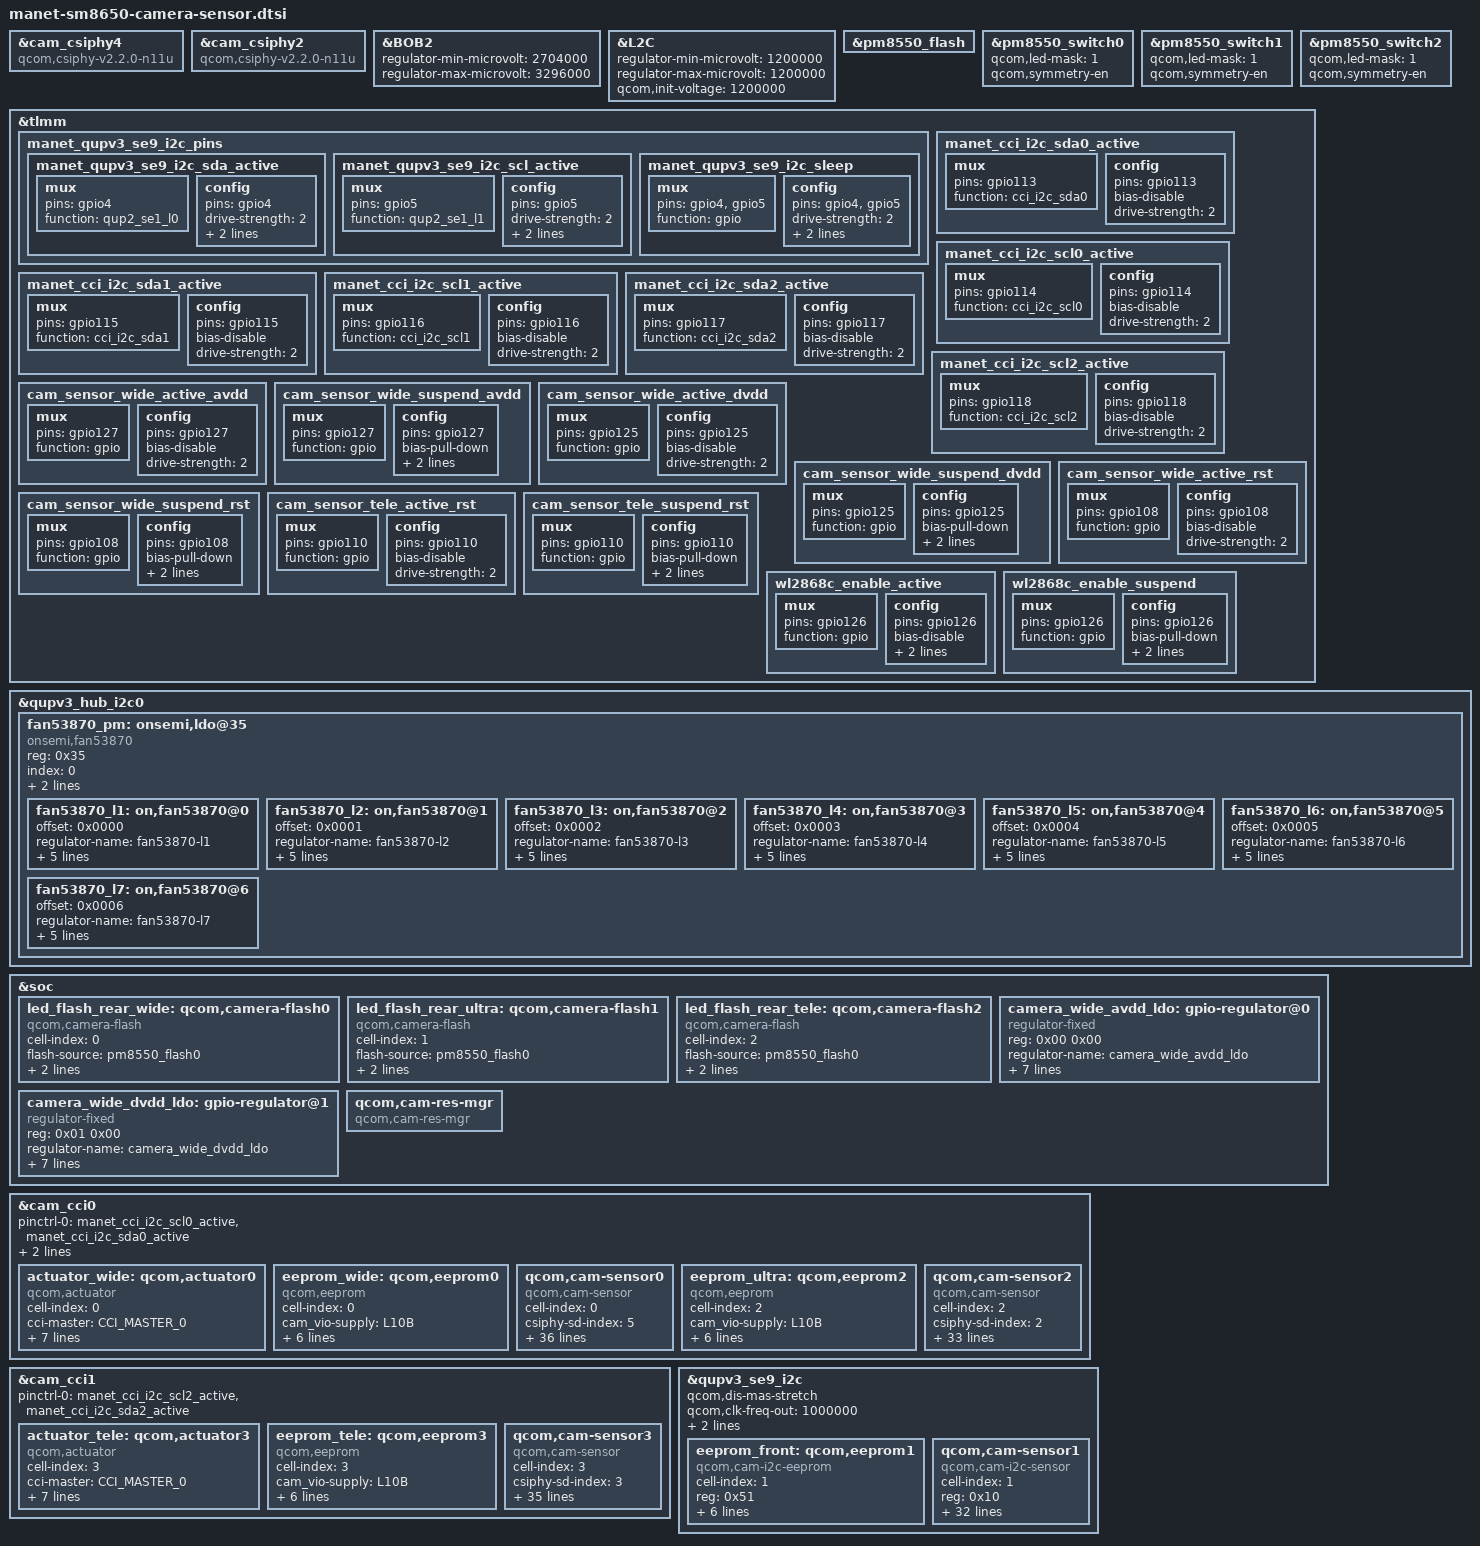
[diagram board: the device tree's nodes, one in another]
#include <dt-bindings/msm-camera.h>

//front
&cam_csiphy4 {
	compatible = "qcom,csiphy-v2.2.0-n11u", "qcom,csiphy";
};

//ultra
&cam_csiphy2 {
	compatible = "qcom,csiphy-v2.2.0-n11u", "qcom,csiphy";
};

&BOB2 {
	regulator-min-microvolt = <2704000>;
	regulator-max-microvolt = <3296000>;
};

&L2C {
	regulator-min-microvolt = <1200000>;
	regulator-max-microvolt = <1200000>;
	qcom,init-voltage = <1200000>;
};

&pm8550_flash {
	status = "ok";
};

&pm8550_switch0 {
	qcom,led-mask = <1>;
	qcom,symmetry-en;
};

&pm8550_switch1 {
	qcom,led-mask = <1>;
	qcom,symmetry-en;
};

&pm8550_switch2 {
	qcom,led-mask = <1>;
	qcom,symmetry-en;
};

&tlmm {
	manet_qupv3_se9_i2c_pins: manet_qupv3_se9_i2c_pins {
		manet_qupv3_se9_i2c_sda_active: manet_qupv3_se9_i2c_sda_active {
			mux {
				pins = "gpio4";
				function = "qup2_se1_l0";
			};

			config {
				pins = "gpio4";
				drive-strength = <2>;
				bias-disable; /* NO PULL */
				qcom,apps;
			};
		};

		manet_qupv3_se9_i2c_scl_active: manet_qupv3_se9_i2c_scl_active {
			mux {
				pins = "gpio5";
				function = "qup2_se1_l1";
			};

			config {
				pins = "gpio5";
				drive-strength = <2>;
				bias-disable; /* NO PULL */
				qcom,apps;
			};
		};

		manet_qupv3_se9_i2c_sleep: manet_qupv3_se9_i2c_sleep {
			mux {
				pins = "gpio4", "gpio5";
				function = "gpio";
			};

			config {
				pins = "gpio4", "gpio5";
				drive-strength = <2>;
				bias-pull-down;
				qcom,remote;
			};
		};
	};


	manet_cci_i2c_sda0_active: manet_cci_i2c_sda0_active {
		mux {
			/* CLK, DATA */
			pins = "gpio113";
			function = "cci_i2c_sda0";
		};

		config {
			pins = "gpio113";
			bias-disable; /* NO PULL */
			drive-strength = <2>; /* 2 MA */
		};
	};

	manet_cci_i2c_scl0_active: manet_cci_i2c_scl0_active {
		mux {
			/* CLK, DATA */
			pins = "gpio114";
			function = "cci_i2c_scl0";
		};

		config {
			pins = "gpio114";
			bias-disable; /* NO PULL */
			drive-strength = <2>; /* 2 MA */
		};
	};

	manet_cci_i2c_sda1_active: manet_cci_i2c_sda1_active {
		mux {
			/* CLK, DATA */
			pins = "gpio115";
			function = "cci_i2c_sda1";
		};

		config {
			pins = "gpio115";
			bias-disable; /* NO PULL */
			drive-strength = <2>; /* 2 MA */
		};
	};

	manet_cci_i2c_scl1_active: manet_cci_i2c_scl1_active {
		mux {
			/* CLK, DATA */
			pins = "gpio116";
			function = "cci_i2c_scl1";
		};

		config {
			pins = "gpio116";
			bias-disable; /* NO PULL */
			drive-strength = <2>; /* 2 MA */
		};
	};

	manet_cci_i2c_sda2_active: manet_cci_i2c_sda2_active {
		mux {
			/* CLK, DATA */
			pins = "gpio117";
			function = "cci_i2c_sda2";
		};

		config {
			pins = "gpio117";
			bias-disable; /* NO PULL */
			drive-strength = <2>; /* 2 MA */
		};
	};

	manet_cci_i2c_scl2_active: manet_cci_i2c_scl2_active {
		mux {
			/* CLK, DATA */
			pins = "gpio118";
			function = "cci_i2c_scl2";
		};

		config {
			pins = "gpio118";
			bias-disable; /* NO PULL */
			drive-strength = <2>; /* 2 MA */
		};
	};

	// WIDE AVDD PINCTL
	cam_sensor_wide_active_avdd: cam_sensor_wide_active_avdd {
		mux {
			pins = "gpio127";
			function = "gpio";
		};

		config {
			pins = "gpio127";
			bias-disable; /* No PULL */
			drive-strength = <2>; /* 2 MA */
		};
	};

	cam_sensor_wide_suspend_avdd: cam_sensor_wide_suspend_avdd {
		mux {
			pins = "gpio127";
			function = "gpio";
		};

		config {
			pins = "gpio127";
			bias-pull-down; /* PULL DOWN */
			drive-strength = <2>; /* 2 MA */
			output-low;
		};
	};

	// WIDE DVDD PINCTL
	cam_sensor_wide_active_dvdd: cam_sensor_wide_active_dvdd {
		mux {
			pins = "gpio125";
			function = "gpio";
		};

		config {
			pins = "gpio125";
			bias-disable; /* No PULL */
			drive-strength = <2>; /* 2 MA */
		};
	};

	cam_sensor_wide_suspend_dvdd: cam_sensor_wide_suspend_dvdd {
		mux {
			pins = "gpio125";
			function = "gpio";
		};

		config {
			pins = "gpio125";
			bias-pull-down; /* PULL DOWN */
			drive-strength = <2>; /* 2 MA */
			output-low;
		};
	};

	// WIDE RST
	cam_sensor_wide_active_rst: cam_sensor_wide_active_rst {
		mux {
			pins = "gpio108";
			function = "gpio";
		};

		config {
			pins = "gpio108";
			bias-disable; /* No PULL */
			drive-strength = <2>; /* 2 MA */
		};
	};

	cam_sensor_wide_suspend_rst: cam_sensor_wide_suspend_rst {
		mux {
			pins = "gpio108";
			function = "gpio";
		};

		config {
			pins = "gpio108";
			bias-pull-down; /* PULL DOWN */
			drive-strength = <2>; /* 2 MA */
			output-low;
		};
	};

	// TELE RST
	cam_sensor_tele_active_rst: cam_sensor_tele_active_rst {
		mux {
			pins = "gpio110";
			function = "gpio";
		};

		config {
			pins = "gpio110";
			bias-disable; /* No PULL */
			drive-strength = <2>; /* 2 MA */
		};
	};

	cam_sensor_tele_suspend_rst: cam_sensor_tele_suspend_rst {
		mux {
			pins = "gpio110";
			function = "gpio";
		};

		config {
			pins = "gpio110";
			bias-pull-down; /* PULL DOWN */
			drive-strength = <2>; /* 2 MA */
			output-low;
		};
	};

	// WL2868C RST
	wl2868c_enable_active: wl2868c_enable_active {
		mux {
			pins = "gpio126";
			function = "gpio";
		};

		config {
			pins = "gpio126";
			bias-disable; /* No PULL */
			drive-strength = <2>; /* 2 MA */
			output-high;
		};
	};

	wl2868c_enable_suspend: wl2868c_enable_suspend {
		mux {
			pins = "gpio126";
			function = "gpio";
		};

		config {
			pins = "gpio126";
			bias-pull-down; /* PULL DOWN */
			drive-strength = <2>; /* 2 MA */
			output-low;
		};
	};
};

&qupv3_hub_i2c0 {
	#address-cells = <1>;
	#size-cells = <0>;
	status = "ok";

	fan53870_pm:onsemi,ldo@35 {
		compatible = "onsemi,fan53870";
		reg = <0x35>;/*slave address*/
		index = <0>;
		pinctrl-names = "wl2868c_enable", "wl2868c_disable";
		pinctrl-0 = <&wl2868c_enable_active>;
		pinctrl-1 = <&wl2868c_enable_suspend>;

		fan53870_l1:on,fan53870@0{
			offset = /bits/ 16 <0x0000>;
			regulator-name ="fan53870-l1";
			regulator-min-microvolt = <528000>;
			regulator-max-microvolt = <1504000>;
			min-dropout-voltage = <225000>;
			init-voltage = <1200000>;
			iout_ua = <650000>;
		};

		fan53870_l2:on,fan53870@1{
			offset = /bits/ 16 <0x0001>;
			regulator-name ="fan53870-l2";
			regulator-min-microvolt = <528000>;
			regulator-max-microvolt = <1504000>;
			min-dropout-voltage = <225000>;
			init-voltage = <1200000>;
			iout_ua = <650000>;
		};

		fan53870_l3:on,fan53870@2{
			offset = /bits/ 16 <0x0002>;
			regulator-name ="fan53870-l3";
			regulator-min-microvolt = <1504000>;
			regulator-max-microvolt = <3400000>;
			min-dropout-voltage = <200000>;
			init-voltage = <2800000>;
			iout_ua = <650000>;
		};

		fan53870_l4:on,fan53870@3{
			offset = /bits/ 16 <0x0003>;
			regulator-name ="fan53870-l4";
			regulator-min-microvolt = <1504000>;
			regulator-max-microvolt = <3400000>;
			min-dropout-voltage = <200000>;
			init-voltage = <2800000>;
			iout_ua = <650000>;
		};

		fan53870_l5:on,fan53870@4{
			offset = /bits/ 16 <0x0004>;
			regulator-name ="fan53870-l5";
			regulator-min-microvolt = <1504000>;
			regulator-max-microvolt = <3400000>;
			min-dropout-voltage = <300000>;
			init-voltage = <2700000>;
			iout_ua = <650000>;
		};

		fan53870_l6:on,fan53870@5{
			offset = /bits/ 16 <0x0005>;
			regulator-name ="fan53870-l6";
			regulator-min-microvolt = <1504000>;
			regulator-max-microvolt = <3400000>;
			min-dropout-voltage = <300000>;
			init-voltage = <2800000>;
			iout_ua = <650000>;
		};

		fan53870_l7:on,fan53870@6{
			offset = /bits/ 16 <0x0006>;
			regulator-name ="fan53870-l7";
			regulator-min-microvolt = <1504000>;
			regulator-max-microvolt = <3400000>;
			min-dropout-voltage = <300000>;
			init-voltage = <2800000>;
			iout_ua = <650000>;
		};
	};
};

&soc {
	led_flash_rear_wide: qcom,camera-flash0 {
		cell-index = <0>;
		compatible = "qcom,camera-flash";
		flash-source = <&pm8550_flash0>;
		torch-source = <&pm8550_torch0>;
		switch-source = <&pm8550_switch0>;
		status = "ok";
	};

	led_flash_rear_ultra: qcom,camera-flash1 {
		cell-index = <1>;
		compatible = "qcom,camera-flash";
		flash-source = <&pm8550_flash0>;
		torch-source = <&pm8550_torch0>;
		switch-source = <&pm8550_switch0>;
		status = "ok";
	};

	led_flash_rear_tele: qcom,camera-flash2 {
		cell-index = <2>;
		compatible = "qcom,camera-flash";
		flash-source = <&pm8550_flash0>;
		torch-source = <&pm8550_torch0>;
		switch-source = <&pm8550_switch0>;
		status = "ok";
	};

	camera_wide_avdd_ldo: gpio-regulator@0 {
		compatible = "regulator-fixed";
		reg = <0x00 0x00>;
		regulator-name = "camera_wide_avdd_ldo";
		regulator-min-microvolt = <2800000>;
		regulator-max-microvolt = <2800000>;
		regulator-enable-ramp-delay = <100>;
		enable-active-high;
		gpio = <&tlmm 127 0>;
		pinctrl-names = "wide_avdd_active", "wide_avdd_suspend";
		pinctrl-0 = <&cam_sensor_wide_active_avdd
					 &cam_sensor_wide_suspend_avdd>;
	};

	camera_wide_dvdd_ldo: gpio-regulator@1 {
		compatible = "regulator-fixed";
		reg = <0x01 0x00>;
		regulator-name = "camera_wide_dvdd_ldo";
		regulator-min-microvolt = <1104000>;
		regulator-max-microvolt = <1104000>;
		regulator-enable-ramp-delay = <100>;
		enable-active-high;
		gpio = <&tlmm 125 0>;
		pinctrl-names = "wide_dvdd_active", "wide_dvdd_suspend";
		pinctrl-0 = <&cam_sensor_wide_active_dvdd
					 &cam_sensor_wide_suspend_dvdd>;
	};

	qcom,cam-res-mgr {
		compatible = "qcom,cam-res-mgr";
		status = "ok";
	};
};

&cam_cci0 {
	pinctrl-0 = <&manet_cci_i2c_scl0_active &manet_cci_i2c_sda0_active>;
	pinctrl-2 = <&manet_cci_i2c_scl1_active &manet_cci_i2c_sda1_active>;

	actuator_wide: qcom,actuator0 {
		cell-index = <0>;
		compatible = "qcom,actuator";
		cci-master = <CCI_MASTER_0>;
		cam_vaf-supply = <&fan53870_l7>;
		cam_vio-supply = <&L10B>;
		regulator-names = "cam_vaf", "cam_vio";
		rgltr-cntrl-support;
		rgltr-min-voltage = <3104000 1800000>;
		rgltr-max-voltage = <3104000 1800000>;
		rgltr-load-current = <103000 20000>;
	};

	eeprom_wide: qcom,eeprom0 {
		cell-index = <0>;
		compatible = "qcom,eeprom";
		cam_vio-supply = <&L10B>;
		regulator-names = "cam_vio";
		rgltr-cntrl-support;
		rgltr-min-voltage = <1800000>;
		rgltr-max-voltage = <1800000>;
		rgltr-load-current = <150000>;
		cci-master = <CCI_MASTER_0>;
		status = "ok";
	};

	// Wide Sensor
	qcom,cam-sensor0 {
		cell-index = <0>;
		compatible = "qcom,cam-sensor";
		csiphy-sd-index = <5>;
		led-flash-src = <&led_flash_rear_wide>;
		eeprom-src = <&eeprom_wide>;
		actuator-src = <&actuator_wide>;
		sensor-position-roll = <90>;
		sensor-position-pitch = <0>;
		sensor-position-yaw = <180>;
		cam_vana-supply = <&camera_wide_avdd_ldo>;
		cam_vio-supply = <&L10B>;
		cam_vdig-supply = <&camera_wide_dvdd_ldo>;
		cam_vaf-supply = <&fan53870_l7>;
		cam_clk-supply = <&cam_cc_titan_top_gdsc>;
		cam_bob2-supply = <&BOB2>;
		regulator-names = "cam_vana", "cam_vio", "cam_vdig",
			"cam_vaf", "cam_clk", "cam_bob2";
		rgltr-cntrl-support;
		rgltr-min-voltage = <2800000 1800000 1104000 3104000 0 2704000>;
		rgltr-max-voltage = <2800000 1800000 1104000 3104000 0 3296000>;
		rgltr-load-current = <150000 150000 150000 103000 0 2000000>;
		gpio-no-mux = <0>;
		pinctrl-names = "cam_default", "cam_suspend";
		pinctrl-0 = <&cam_sensor_mclk0_active
			&cam_sensor_wide_active_rst>;
		pinctrl-1 = <&cam_sensor_mclk0_suspend
			&cam_sensor_wide_suspend_rst>;
		gpios = <&tlmm 100 0>, <&tlmm 108 0>;
		gpio-reset = <1>;
		gpio-req-tbl-num = <0 1>;
		gpio-req-tbl-flags = <1 0>;
		gpio-req-tbl-label = "CAMIF_MCLK0", "CAM_RESET_WIDE";
		cci-master = <CCI_MASTER_0>;
		clocks = <&camcc CAM_CC_MCLK0_CLK>;
		clock-names = "cam_clk";
		clock-cntl-level = "nominal";
		clock-rates = <19200000>;
		status = "ok";
	};

	eeprom_ultra: qcom,eeprom2 {
		cell-index = <2>;
		compatible = "qcom,eeprom";
		cam_vio-supply = <&L10B>;
		regulator-names = "cam_vio";
		rgltr-cntrl-support;
		rgltr-min-voltage = <1800000>;
		rgltr-max-voltage = <1800000>;
		rgltr-load-current = <150000>;
		cci-master = <CCI_MASTER_1>;
		status = "ok";
	};

	// Ultra Sensor
	qcom,cam-sensor2 {
		cell-index = <2>;
		compatible = "qcom,cam-sensor";
		csiphy-sd-index = <2>;
		eeprom-src = <&eeprom_ultra>;
		led-flash-src = <&led_flash_rear_ultra>;
		sensor-position-roll = <90>;
		sensor-position-pitch = <0>;
		sensor-position-yaw = <180>;
		cam_vana-supply = <&fan53870_l5>;
		cam_vio-supply  = <&L10B>;
		cam_vdig-supply = <&fan53870_l2>;
		cam_clk-supply  = <&cam_cc_titan_top_gdsc>;
		cam_bob2-supply = <&BOB2>;
		regulator-names = "cam_vana", "cam_vio", "cam_vdig",
			"cam_clk", "cam_bob2";
		rgltr-cntrl-support;
		rgltr-min-voltage = <2800000 1800000 1200000 0 2704000>;
		rgltr-max-voltage = <2800000 1800000 1200000 0 3296000>;
		rgltr-load-current = <150000 150000 150000 0 2000000>;
		gpio-no-mux = <0>;
		pinctrl-names = "cam_default", "cam_suspend";
		pinctrl-0 = <&cam_sensor_mclk1_active
			&cam_sensor_active_rst3>;
		pinctrl-1 = <&cam_sensor_mclk1_suspend
			&cam_sensor_suspend_rst3>;
		gpios = <&tlmm 101 0>, <&tlmm 109 0>;
		gpio-reset = <1>;
		gpio-req-tbl-num = <0 1>;
		gpio-req-tbl-flags = <1 0>;
		gpio-req-tbl-label = "CAMIF_MCLK1", "CAM_RESET3";
		cci-master = <CCI_MASTER_1>;
		clocks = <&camcc CAM_CC_MCLK1_CLK>;
		clock-names = "cam_clk";
		clock-cntl-level = "nominal";
		clock-rates = <19200000>;
		status = "ok";
	};
};

&cam_cci1 {
	pinctrl-0 = <&manet_cci_i2c_scl2_active &manet_cci_i2c_sda2_active>;

	actuator_tele: qcom,actuator3 {
		cell-index = <3>;
		compatible = "qcom,actuator";
		cci-master = <CCI_MASTER_0>;
		cam_vaf-supply = <&fan53870_l6>;
		cam_vio-supply = <&L10B>;
		regulator-names = "cam_vaf", "cam_vio";
		rgltr-cntrl-support;
		rgltr-min-voltage = <2800000 1800000>;
		rgltr-max-voltage = <2800000 1800000>;
		rgltr-load-current = <103000 20000>;
	};

	eeprom_tele: qcom,eeprom3 {
		cell-index = <3>;
		compatible = "qcom,eeprom";
		cam_vio-supply = <&L10B>;
		regulator-names = "cam_vio";
		rgltr-cntrl-support;
		rgltr-min-voltage = <1800000>;
		rgltr-max-voltage = <1800000>;
		rgltr-load-current = <150000>;
		cci-master = <CCI_MASTER_0>;
		status = "ok";
	};

	// Tele Sensor
	qcom,cam-sensor3 {
		cell-index = <3>;
		compatible = "qcom,cam-sensor";
		csiphy-sd-index = <3>;
		eeprom-src = <&eeprom_tele>;
		actuator-src = <&actuator_tele>;
		led-flash-src = <&led_flash_rear_tele>;
		sensor-position-roll = <90>;
		sensor-position-pitch = <0>;
		sensor-position-yaw = <180>;
		cam_vana-supply = <&fan53870_l4>;
		cam_vio-supply  = <&L10B>;
		cam_vdig-supply = <&fan53870_l1>;
		cam_vaf-supply  = <&fan53870_l6>;
		cam_clk-supply  = <&cam_cc_titan_top_gdsc>;
		cam_bob2-supply = <&BOB2>;
		regulator-names = "cam_vana", "cam_vio", "cam_vdig",
			"cam_vaf", "cam_clk", "cam_bob2";
		rgltr-cntrl-support;
		rgltr-min-voltage = <2800000 1800000 1200000 2800000 0 2704000>;
		rgltr-max-voltage = <2800000 1800000 1200000 2800000 0 3296000>;
		rgltr-load-current = <150000 150000 150000 103000 0 2000000>;
		gpio-no-mux = <0>;
		pinctrl-names = "cam_default", "cam_suspend";
		pinctrl-0 = <&cam_sensor_mclk3_active
						&cam_sensor_tele_active_rst>;
		pinctrl-1 = <&cam_sensor_mclk3_suspend
						&cam_sensor_tele_suspend_rst>;
		gpios = <&tlmm 103 0>, <&tlmm 110 0>;
		gpio-reset = <1>;
		gpio-req-tbl-num = <0 1>;
		gpio-req-tbl-flags = <1 0>;
		gpio-req-tbl-label = "CAMIF_MCLK3", "CAM_RESET3";
		cci-master = <CCI_MASTER_0>;
		clocks = <&camcc CAM_CC_MCLK3_CLK>;
		clock-names = "cam_clk";
		clock-cntl-level = "nominal";
		clock-rates = <19200000>;
		status = "ok";
	};
};

&qupv3_se9_i2c {
	status = "ok";
	qcom,dis-mas-stretch;
	qcom,clk-freq-out = <1000000>;

	pinctrl-0 = <&manet_qupv3_se9_i2c_sda_active>, <&manet_qupv3_se9_i2c_scl_active>;

	eeprom_front: qcom,eeprom1 {
		cell-index = <1>;
		reg = <0x51>;
		compatible = "qcom,cam-i2c-eeprom";
		cam_vio-supply = <&L10B>;
		regulator-names = "cam_vio";
		rgltr-cntrl-support;
		rgltr-min-voltage = <1800000>;
		rgltr-max-voltage = <1800000>;
		rgltr-load-current = <150000>;
		status = "ok";
	};

    //front sensor
	qcom,cam-sensor1 {
		cell-index = <1>;
		reg = <0x10>;
		compatible = "qcom,cam-i2c-sensor";
		csiphy-sd-index = <4>;
		sensor-position-roll = <270>;
		sensor-position-pitch = <0>;
		sensor-position-yaw = <0>;
		eeprom-src = <&eeprom_front>;
		cam_vana-supply = <&fan53870_l3>;
		cam_vio-supply = <&L10B>;
		cam_vdig-supply = <&L2C>;
		cam_clk-supply = <&cam_cc_titan_top_gdsc>;
		cam_bob2-supply = <&BOB2>;
		regulator-names = "cam_vana", "cam_vio", "cam_vdig", "cam_clk", "cam_bob2";
		rgltr-cntrl-support;
		rgltr-min-voltage = <2800000 1800000 1200000 0 2704000>;
		rgltr-max-voltage = <2800000 1800000 1200000 0 3296000>;
		rgltr-load-current = <150000 150000 150000 0 2000000>;
		gpio-no-mux = <0>;
		pinctrl-names = "cam_default", "cam_suspend";
		pinctrl-0 = <&cam_sensor_mclk4_active
				 &cam_sensor_active_rst4>;
		pinctrl-1 = <&cam_sensor_mclk4_suspend
				 &cam_sensor_suspend_rst4>;
		gpios = <&tlmm 104 0>,
			<&tlmm 7 0>;
		gpio-reset = <1>;
		gpio-req-tbl-num = <0 1>;
		gpio-req-tbl-flags = <1 0>;
		gpio-req-tbl-label = "CAMIF_MCLK4",
					"CAM_RESET4";
		clocks = <&camcc CAM_CC_MCLK4_CLK>;
		clock-names = "cam_clk";
		clock-cntl-level = "nominal";
		clock-rates = <19200000>;
		status = "ok";
	};
};

